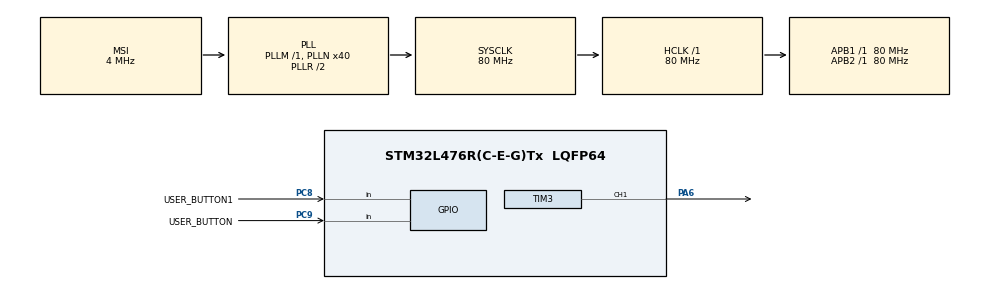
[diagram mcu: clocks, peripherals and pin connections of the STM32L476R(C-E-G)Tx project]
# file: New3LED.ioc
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Dma.Request0=TIM3_CH1/TRIG
Dma.TIM3_CH1/TRIG.0.Direction=DMA_MEMORY_TO_PERIPH
Dma.TIM3_CH1/TRIG.0.Instance=DMA1_Channel6
Dma.TIM3_CH1/TRIG.0.MemDataAlignment=DMA_MDATAALIGN_BYTE
Dma.TIM3_CH1/TRIG.0.MemInc=DMA_MINC_ENABLE
Dma.TIM3_CH1/TRIG.0.Mode=DMA_NORMAL
Dma.TIM3_CH1/TRIG.0.PeriphDataAlignment=DMA_PDATAALIGN_HALFWORD
Dma.TIM3_CH1/TRIG.0.PeriphInc=DMA_PINC_DISABLE
Dma.TIM3_CH1/TRIG.0.Priority=DMA_PRIORITY_LOW
Mcu.Family=STM32L4
Mcu.Name=STM32L476R(C-E-G)Tx
Mcu.Package=LQFP64
NVIC.DMA1_Channel6_IRQn=true\:0\:0\:false\:false\:true\:false\:true\:true
NVIC.PriorityGroup=NVIC_PRIORITYGROUP_4
PA13\ (JTMS-SWDIO).Mode=Serial_Wire
PA13\ (JTMS-SWDIO).Signal=SYS_JTMS-SWDIO
PA14\ (JTCK-SWCLK).Mode=Serial_Wire
PA14\ (JTCK-SWCLK).Signal=SYS_JTCK-SWCLK
PA6.Signal=S_TIM3_CH1
PC8.GPIO_Label=USER_BUTTON1
PC8.Signal=GPIO_Input
PC9.GPIO_Label=USER_BUTTON
PC9.GPIO_PuPd=GPIO_PULLUP
PC9.Signal=GPIO_Input
ProjectManager.HeapSize=0x200
ProjectManager.StackSize=0x400
ProjectManager.TargetToolchain=STM32CubeIDE
RCC.AHBFreq_Value=80000000
RCC.APB1Freq_Value=80000000
RCC.APB1TimFreq_Value=80000000
RCC.APB2Freq_Value=80000000
RCC.APB2TimFreq_Value=80000000
RCC.CortexFreq_Value=80000000
RCC.HCLKFreq_Value=80000000
RCC.HSE_VALUE=8000000
RCC.HSI_VALUE=16000000
RCC.LSE_VALUE=32768
RCC.MSI_VALUE=4000000
RCC.PLLN=40
RCC.SYSCLKFreq_VALUE=80000000
RCC.SYSCLKSource=RCC_SYSCLKSOURCE_PLLCLK
RCC.VCOOutputFreq_Value=160000000
SH.S_TIM3_CH1.0=TIM3_CH1,PWM Generation1 CH1
TIM3.Channel-PWM\ Generation1\ CH1=TIM_CHANNEL_1
TIM3.Period=99
VP_TIM3_VS_ClockSourceINT.Mode=Internal
board=custom

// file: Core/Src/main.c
/* USER CODE BEGIN Header */
/**
  ******************************************************************************
  * @file           : main.c
  * @brief          : Main program body
  ******************************************************************************
  * @attention
  *
  * Copyright (c) 2024 STMicroelectronics.
  * All rights reserved.
  *
  * This software is licensed under terms that can be found in the LICENSE file
  * in the root directory of this software component.
  * If no LICENSE file comes with this software, it is provided AS-IS.
  *
  ******************************************************************************
  */
/* USER CODE END Header */

/* USER CODE BEGIN Includes */
#include <stdbool.h>
#include "ws2812b.h"
#include "main.h"
#include "dma.h"
#include "tim.h"
#include "gpio.h"

const uint8_t gamma8[] = {
    0,  0,  0,  0,  0,  0,  0,  0,  0,  0,  0,  0,  0,  0,  0,  0,
    0,  0,  0,  0,  0,  0,  0,  0,  0,  0,  0,  0,  1,  1,  1,  1,
    1,  1,  1,  1,  1,  1,  1,  1,  1,  2,  2,  2,  2,  2,  2,  2,
    2,  3,  3,  3,  3,  3,  3,  3,  4,  4,  4,  4,  4,  5,  5,  5,
    5,  6,  6,  6,  6,  7,  7,  7,  7,  8,  8,  8,  9,  9,  9, 10,
   10, 10, 11, 11, 11, 12, 12, 13, 13, 13, 14, 14, 15, 15, 16, 16,
   17, 17, 18, 18, 19, 19, 20, 20, 21, 21, 22, 22, 23, 24, 24, 25,
   25, 26, 27, 27, 28, 29, 29, 30, 31, 32, 32, 33, 34, 35, 35, 36,
   37, 38, 39, 39, 40, 41, 42, 43, 44, 45, 46, 47, 48, 49, 50, 50,
   51, 52, 54, 55, 56, 57, 58, 59, 60, 61, 62, 63, 64, 66, 67, 68,
   69, 70, 72, 73, 74, 75, 77, 78, 79, 81, 82, 83, 85, 86, 87, 89,
   90, 92, 93, 95, 96, 98, 99,101,102,104,105,107,109,110,112,114,
  115,117,119,120,122,124,126,127,129,131,133,135,137,138,140,142,
  144,146,148,150,152,154,156,158,160,162,164,167,169,171,173,175,
  177,180,182,184,186,189,191,193,196,198,200,203,205,208,210,213,
  215,218,220,223,225,228,231,233,236,239,241,244,247,249,252,255 };

/* USER CODE END Includes */

void SystemClock_Config(void);

/* USER CODE BEGIN 0 */
bool pressed = false;

//bool is_button_pressed(void) {
//
//    if (HAL_GPIO_ReadPin(USER_BUTTON_GPIO_Port, USER_BUTTON_Pin) == GPIO_PIN_SET) {
//      return true;
//    } else {
//      return false;
//    }
//}

bool is_user_button_pressed(int button) {
  switch (button) {
  case 0:
	    if (HAL_GPIO_ReadPin(USER_BUTTON_GPIO_Port, USER_BUTTON_Pin) == GPIO_PIN_SET) {
	      return true;
	    } else {
	      return false;
	    }
  case 1:
	    if (HAL_GPIO_ReadPin(USER_BUTTON1_GPIO_Port, USER_BUTTON1_Pin) == GPIO_PIN_SET) {
	      return true;
	    } else {
	      return false;
	    }

  default:
    return false;
  }
}

/* USER CODE END 0 */

int main(void)
{

  /* MCU Configuration--------------------------------------------------------*/

  /* Reset of all peripherals, Initializes the Flash interface and the Systick. */
  HAL_Init();

  /* Configure the system clock */
  SystemClock_Config();

  /* Initialize all configured peripherals */
  MX_GPIO_Init();
  MX_DMA_Init();
  MX_TIM3_Init();
  /* USER CODE BEGIN 2 */
//  HAL_TIM_Base_Start(&htim3);
//
//  uint8_t test[40 + 7 * 24 + 1] = {0};
//
//  // Zerowanie kolorow wszystkich diod
//  for (int i = 0; i < 7 * 24; i++)
//    test[40 + i] = 32;
//
//  // Wlącz jedną diodę
//  test[40] = 64;
//
//  // Stan wysoki na koncu
//  test[40 + 7 * 24] = 100;
//
//  HAL_TIM_PWM_Start_DMA(&htim3, TIM_CHANNEL_1, &test, sizeof(test));

  /* USER CODE END 2 */

  /* Infinite loop */
  /* USER CODE BEGIN WHILE */
  ws2812b_init();
  bool user_button_pressed = false;
  int led = 0;
  bool directionReverse = false;
  int currentColor = 1;

  while (1)
  {
    /* USER CODE END WHILE */
  	  if (is_user_button_pressed(1)) {
  		  if(user_button_pressed == false){
  			  user_button_pressed = true;
  			directionReverse = !directionReverse;
  		  }
  	  }
  	  else if (is_user_button_pressed(0)) {
  		  if(user_button_pressed == false){
  			  user_button_pressed = true;
  			directionReverse = !directionReverse;
  		  }
  	  }
  	  else{
  		  user_button_pressed = false;
  	  }

	  if(directionReverse) {
	          led++;
	      } else {
	          led--;
	      }

	      // Zapobieganie przekroczeniu zakresu
	      if(led >= 6) {
	          led = 0;
	      } else if(led < 0) {
	          led = 5;
	      }

	      uint8_t r = gamma8[rand() % 70];
	      uint8_t g = gamma8[rand() % 70];
	      uint8_t b = gamma8[rand() % 70];

	      ws2812b_set_color(led, r, g, b);
	      ws2812b_update();
	      HAL_Delay(100);
  }
}

void SystemClock_Config(void)
{
  RCC_OscInitTypeDef RCC_OscInitStruct = {0};
  RCC_ClkInitTypeDef RCC_ClkInitStruct = {0};

  /** Configure the main internal regulator output voltage
  */
  if (HAL_PWREx_ControlVoltageScaling(PWR_REGULATOR_VOLTAGE_SCALE1) != HAL_OK)
  {
    Error_Handler();
  }

  /** Initializes the RCC Oscillators according to the specified parameters
  * in the RCC_OscInitTypeDef structure.
  */
  RCC_OscInitStruct.OscillatorType = RCC_OSCILLATORTYPE_MSI;
  RCC_OscInitStruct.MSIState = RCC_MSI_ON;
  RCC_OscInitStruct.MSICalibrationValue = 0;
  RCC_OscInitStruct.MSIClockRange = RCC_MSIRANGE_6;
  RCC_OscInitStruct.PLL.PLLState = RCC_PLL_ON;
  RCC_OscInitStruct.PLL.PLLSource = RCC_PLLSOURCE_MSI;
  RCC_OscInitStruct.PLL.PLLM = 1;
  RCC_OscInitStruct.PLL.PLLN = 40;
  RCC_OscInitStruct.PLL.PLLP = RCC_PLLP_DIV7;
  RCC_OscInitStruct.PLL.PLLQ = RCC_PLLQ_DIV2;
  RCC_OscInitStruct.PLL.PLLR = RCC_PLLR_DIV2;
  if (HAL_RCC_OscConfig(&RCC_OscInitStruct) != HAL_OK)
  {
    Error_Handler();
  }

  /** Initializes the CPU, AHB and APB buses clocks
  */
  RCC_ClkInitStruct.ClockType = RCC_CLOCKTYPE_HCLK|RCC_CLOCKTYPE_SYSCLK
                              |RCC_CLOCKTYPE_PCLK1|RCC_CLOCKTYPE_PCLK2;
  RCC_ClkInitStruct.SYSCLKSource = RCC_SYSCLKSOURCE_PLLCLK;
  RCC_ClkInitStruct.AHBCLKDivider = RCC_SYSCLK_DIV1;
  RCC_ClkInitStruct.APB1CLKDivider = RCC_HCLK_DIV1;
  RCC_ClkInitStruct.APB2CLKDivider = RCC_HCLK_DIV1;

  if (HAL_RCC_ClockConfig(&RCC_ClkInitStruct, FLASH_LATENCY_4) != HAL_OK)
  {
    Error_Handler();
  }
}

void Error_Handler(void)
{
  __disable_irq();
  while (1)
  {
  }
}
